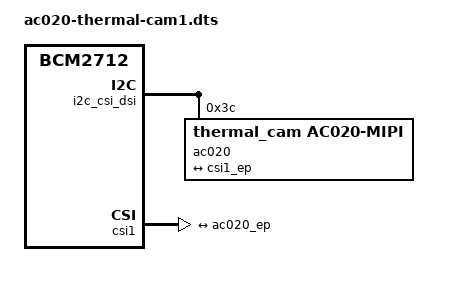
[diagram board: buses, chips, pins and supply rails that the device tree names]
// SPDX-License-Identifier: GPL-2.0
/*
 * Device Tree Overlay — AC020 Thermal Camera on CAM1
 * Raspberry Pi CM5 / Pi 5  (RP1 CSI receiver, Linux 6.12.y)
 *
 * CAM1 is the standard single-camera FPC connector on the Pi 5 and
 * on most CM5 carrier boards.
 *
 * Compile & install:
 *   make dtbo && sudo make install_dtbo
 *
 * Enable in /boot/firmware/config.txt:
 *   dtoverlay=ac020-thermal-cam1
 */

/dts-v1/;
/plugin/;

/ {
	compatible = "brcm,bcm2712";

	/* Register the sensor on the CAM1 I2C bus */
	fragment@0 {
		target = <&i2c_csi_dsi>;
		__overlay__ {
			#address-cells = <1>;
			#size-cells    = <0>;
			status         = "okay";

			ac020: ac020@3c {
				compatible = "thermal_cam,ac020-mipi";
				reg        = <0x3c>;
				status     = "okay";

				port {
					ac020_ep: endpoint {
						remote-endpoint = <&csi1_ep>;
						data-lanes      = <1 2>;
						clock-noncontinuous;
						link-frequencies = /bits/ 64 <80000000>;
					};
				};
			};
		};
	};

	/* Enable the RP1 CSI-2 receiver (CAM1 = csi1) */
	fragment@1 {
		target = <&csi1>;
		__overlay__ {
			status = "okay";

			port {
				csi1_ep: endpoint {
					remote-endpoint = <&ac020_ep>;
					data-lanes      = <1 2>;
					clock-noncontinuous;
				};
			};
		};
	};
};
